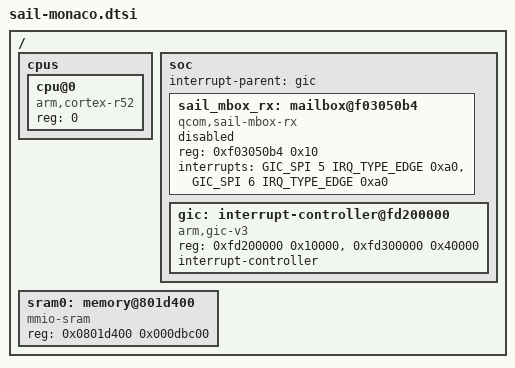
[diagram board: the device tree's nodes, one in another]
/*
 * Copyright The Zephyr Project Contributors
 * SPDX-License-Identifier: Apache-2.0
 */

#include <arm/armv8-r.dtsi>
#include <zephyr/dt-bindings/interrupt-controller/arm-gic.h>

/ {
	cpus {
		#address-cells = <1>;
		#size-cells = <0>;

		cpu@0 {
			compatible = "arm,cortex-r52";
			reg = <0>;
			device_type = "cpu";
		};
	};

	soc {
		interrupt-parent = <&gic>;

		sail_mbox_rx: mailbox@f03050b4 {
			compatible = "qcom,sail-mbox-rx";
			reg = <0xf03050b4 0x10>;
			interrupts = <GIC_SPI 5 IRQ_TYPE_EDGE 0xa0>,
				     <GIC_SPI 6 IRQ_TYPE_EDGE 0xa0>;
			interrupt-names = "nonsecure", "secure";
			#mbox-cells = <1>;
			status = "disabled";
		};

		gic: interrupt-controller@fd200000 {
			compatible = "arm,gic-v3", "arm,gic";
			reg = <0xfd200000 0x10000>,
			      <0xfd300000 0x40000>;
			interrupt-controller;
			#interrupt-cells = <4>;
			status = "okay";
		};
	};

	sram0: memory@801d400 {
		compatible = "mmio-sram";
		reg = <0x0801d400 0x000dbc00>;
	};
};
